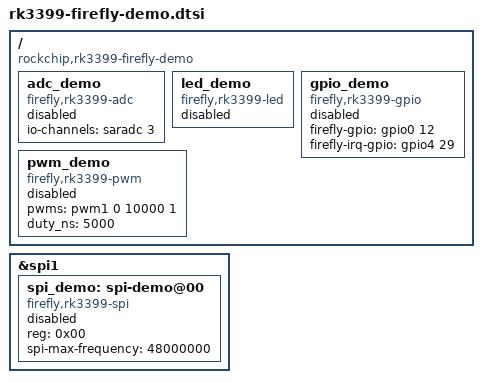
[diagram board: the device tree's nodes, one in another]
/*
 * (C) Copyright 2022 FireflyTeam <service@t-firefly.com>
 *
 * SPDX-License-Identifier:	GPL-2.0+
 */

/ {
    compatible = "rockchip,rk3399-firefly-demo", "rockchip,rk3399";

    adc_demo: adc_demo {
        status = "disabled";
        compatible = "firefly,rk3399-adc";
        io-channels = <&saradc 3>;
    };

    led_demo: led_demo {
        status = "disabled";
        compatible = "firefly,rk3399-led";
    };

    gpio_demo: gpio_demo {
        status = "disabled";
        compatible = "firefly,rk3399-gpio";
        firefly-gpio = <&gpio0 12 GPIO_ACTIVE_HIGH>;          /* GPIO0_B4 */
        firefly-irq-gpio = <&gpio4 29 IRQ_TYPE_EDGE_RISING>;  /* GPIO4_D5 */
    };

    pwm_demo: pwm_demo {
        status = "disabled";
        compatible = "firefly,rk3399-pwm";
        pwms = <&pwm1 0 10000 1>;   //pwm1:PWM number   0 10000:PWM period in nanoseconds  1:polarity
        duty_ns = <5000>;           //pwm duty cycle activation time, unit ns
    };
};


/* Firefly SPI demo */
&spi1 {
       spi_demo: spi-demo@00{
               status = "disabled";
               compatible = "firefly,rk3399-spi";
               reg = <0x00>;
               spi-max-frequency = <48000000>;
               /* rk3399 driver support SPI_CPOL | SPI_CPHA | SPI_CS_HIGH */
               //spi-cpha;             /* SPI mode: CPHA=1 */
               //spi-cpol;             /* SPI mode: CPOL=1 */
               //spi-cs-high;
       };
};

//&spidev0 {
//    status = "disabled";
//};
